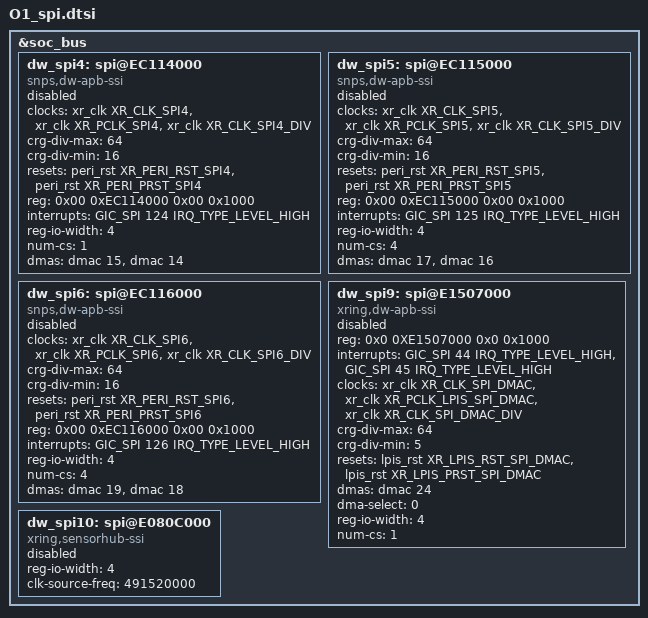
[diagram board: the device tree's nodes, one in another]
// SPDX-License-Identifier: (GPL-2.0+ OR MIT)
/*
 * Copyright 2023 XiaoMi
 *
 */

#include "O1.dtsi"
#include "O1_clock.dtsi"
#include "O1_reset.dtsi"

&soc_bus{
    dw_spi4: spi@EC114000 {
        compatible = "snps,dw-apb-ssi";
        clocks = <&xr_clk XR_CLK_SPI4>, <&xr_clk XR_PCLK_SPI4>, <&xr_clk XR_CLK_SPI4_DIV>;
        clock-names = "clk", "pclk", "clk_div";
        crg-div-max = <64>;
        crg-div-min = <16>;
        resets = <&peri_rst XR_PERI_RST_SPI4>, <&peri_rst XR_PERI_PRST_SPI4>;
        reset-names = "rst", "prst";
        reg = <0x00 0xEC114000 0x00 0x1000>;
        interrupts = <GIC_SPI 124 IRQ_TYPE_LEVEL_HIGH>;
        reg-io-width = <4>;
        num-cs = <1>;
        #address-cells = <1>;
        #size-cells = <0>;
        dmas = <&dmac 15>, <&dmac 14>;
        dma-names = "tx", "rx";
        status = "disabled";
    };

    dw_spi5: spi@EC115000 {
        compatible = "snps,dw-apb-ssi";
        clocks = <&xr_clk XR_CLK_SPI5>, <&xr_clk XR_PCLK_SPI5>, <&xr_clk XR_CLK_SPI5_DIV>;
        clock-names = "clk", "pclk", "clk_div";
        crg-div-max = <64>;
        crg-div-min = <16>;
        resets = <&peri_rst XR_PERI_RST_SPI5>, <&peri_rst XR_PERI_PRST_SPI5>;
        reset-names = "rst", "prst";
        reg = <0x00 0xEC115000 0x00 0x1000>;
        interrupts = <GIC_SPI 125 IRQ_TYPE_LEVEL_HIGH>;
        reg-io-width = <4>;
        num-cs = <4>;
        #address-cells = <1>;
        #size-cells = <0>;
        dmas = <&dmac 17>, <&dmac 16>;
        dma-names = "tx", "rx";
        status = "disabled";
    };

    dw_spi6: spi@EC116000 {
        compatible = "snps,dw-apb-ssi";
        clocks = <&xr_clk XR_CLK_SPI6>, <&xr_clk XR_PCLK_SPI6>, <&xr_clk XR_CLK_SPI6_DIV>;
        clock-names = "clk", "pclk", "clk_div";
        crg-div-max = <64>;
        crg-div-min = <16>;
        resets = <&peri_rst XR_PERI_RST_SPI6>, <&peri_rst XR_PERI_PRST_SPI6>;
        reset-names = "rst", "prst";
        reg = <0x00 0xEC116000 0x00 0x1000>;
        interrupts = <GIC_SPI 126 IRQ_TYPE_LEVEL_HIGH>;
        reg-io-width = <4>;
        num-cs = <4>;
        #address-cells = <1>;
        #size-cells = <0>;
        dmas = <&dmac 19>, <&dmac 18>;
        dma-names = "tx", "rx";
        status = "disabled";
    };

    dw_spi9: spi@E1507000 {
        compatible = "xring,dw-apb-ssi";
        reg = <0x0 0XE1507000 0x0 0x1000>;
        interrupts = <GIC_SPI 44 IRQ_TYPE_LEVEL_HIGH>,
                     <GIC_SPI 45 IRQ_TYPE_LEVEL_HIGH>;
        clocks = <&xr_clk XR_CLK_SPI_DMAC>, <&xr_clk XR_PCLK_LPIS_SPI_DMAC>, <&xr_clk XR_CLK_SPI_DMAC_DIV>;
        clock-names = "clk", "pclk", "clk_div";
        crg-div-max = <64>;
        crg-div-min = <5>;
        resets = <&lpis_rst XR_LPIS_RST_SPI_DMAC>, <&lpis_rst XR_LPIS_PRST_SPI_DMAC>;
        reset-names = "rst", "prst";
        dma-names = "rx";
        dmas = <&dmac 24>;
        dma-select = <0>;
        reg-io-width = <4>;
        num-cs = <1>;
        #address-cells = <1>;
        #size-cells = <0>;
        status = "disabled";
    };

    dw_spi10: spi@E080C000 {
        compatible = "xring,sensorhub-ssi";
        reg-io-width = <4>;
        status = "disabled";
        clk-source-freq = <491520000>; /* 491.52MHz */
    };
};
